VERSION ""

NS_ :

BS_:
BU_:
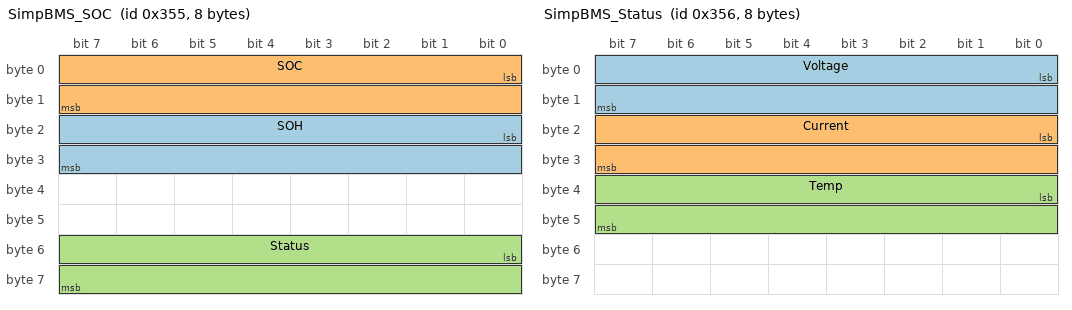
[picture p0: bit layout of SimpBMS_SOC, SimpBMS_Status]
BO_ 853 SimpBMS_SOC: 8 Vector__XXX
   SG_ SOH : 16|16@1+ (1,0) [0|0] "%" Vector__XXX
   SG_ SOC : 0|16@1+ (1,0) [0|0] "%" Vector__XXX
   SG_ Status : 48|16@1+ (1,0) [0|0] "" Vector__XXX

BO_ 854 SimpBMS_Status: 8 Vector__XXX
   SG_ Voltage : 0|16@1+ (0.01,0) [0|0] "V" Vector__XXX
   SG_ Current : 16|16@1+ (0.1,0) [0|0] "A" Vector__XXX
   SG_ Temp : 32|16@1+ (0.1,0) [0|0] "C" Vector__XXX

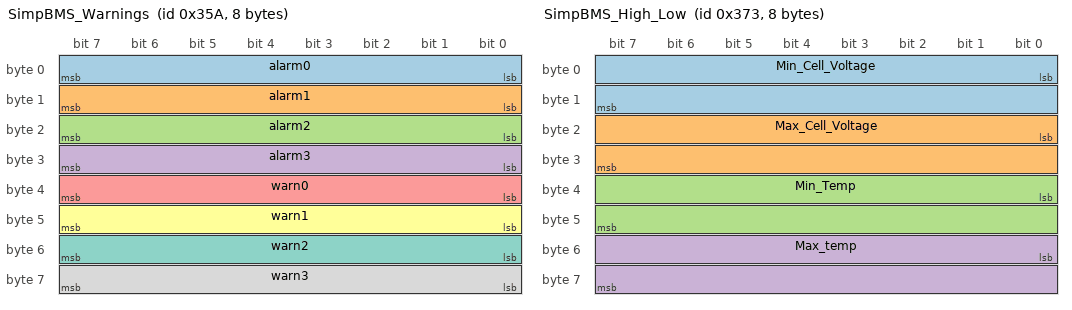
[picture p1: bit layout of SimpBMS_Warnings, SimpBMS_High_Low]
BO_ 858 SimpBMS_Warnings: 8 Vector__XXX
   SG_ alarm0 : 0|8@1+ (1,0) [0|0] "" Vector__XXX
   SG_ alarm1 : 8|8@1+ (1,0) [0|0] "" Vector__XXX
   SG_ alarm2 : 16|8@1+ (1,0) [0|0] "" Vector__XXX
   SG_ alarm3 : 24|8@1+ (1,0) [0|0] "" Vector__XXX
   SG_ warn0 : 32|8@1+ (1,0) [0|0] "" Vector__XXX
   SG_ warn1 : 40|8@1+ (1,0) [0|0] "" Vector__XXX
   SG_ warn2 : 48|8@1+ (1,0) [0|0] "" Vector__XXX
   SG_ warn3 : 56|8@1+ (1,0) [0|0] "" Vector__XXX

BO_ 883 SimpBMS_High_Low: 8 Vector__XXX
   SG_ Min_Cell_Voltage : 0|16@1+ (1,0) [0|0] "mV" Vector__XXX
   SG_ Max_Cell_Voltage : 16|16@1+ (1,0) [0|0] "mV" Vector__XXX
   SG_ Min_Temp : 32|16@1+ (1,0) [0|0] "K" Vector__XXX
   SG_ Max_temp : 48|16@1+ (1,0) [0|0] "K" Vector__XXX

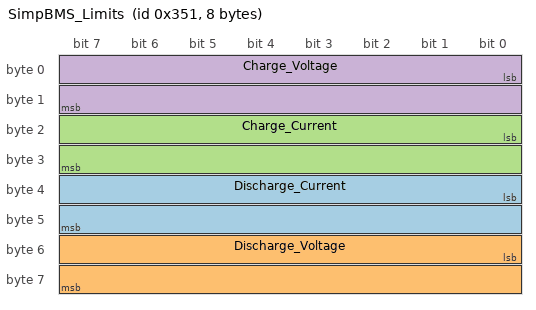
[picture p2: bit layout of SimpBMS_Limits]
BO_ 849 SimpBMS_Limits: 8 Vector__XXX
   SG_ Discharge_Current : 32|16@1+ (0.1,0) [0|0] "A" Vector__XXX
   SG_ Discharge_Voltage : 48|16@1+ (0.1,0) [0|0] "V" Vector__XXX
   SG_ Charge_Current : 16|16@1+ (0.1,0) [0|0] "A" Vector__XXX
   SG_ Charge_Voltage : 0|16@1+ (0.1,0) [0|0] "V" Vector__XXX

BA_DEF_ BO_ "GenMsgBackgroundColor" STRING ;
BA_DEF_ BO_ "GenMsgForegroundColor" STRING ;
BA_DEF_DEF_ "GenMsgBackgroundColor" "#ffffff";
BA_DEF_DEF_ "GenMsgForegroundColor" "#000000";
VAL_ 853 Status 5 "Error" 4 "Precharge" 3 "Charge" 2 "Drive" 1 "Ready";

CM_ BO_ 854 "msdsbj";
